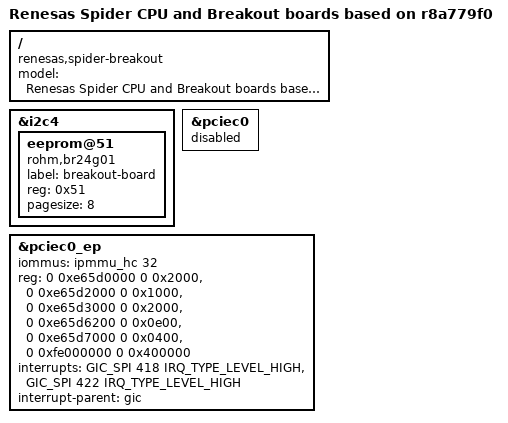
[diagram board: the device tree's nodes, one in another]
// SPDX-License-Identifier: (GPL-2.0 or MIT)
/*
 * Device Tree Source for the Spider CPU and BreakOut boards
 * (PCIe EP mode with DW PCIe eDMA used for NTB transport)
 *
 * Based on the base r8a779f0-spider.dts.
 *
 * Copyright (C) 2025 Renesas Electronics Corp.
 */

/dts-v1/;
#include "r8a779f0-spider-cpu.dtsi"
#include "r8a779f0-spider-ethernet.dtsi"

/ {
	model = "Renesas Spider CPU and Breakout boards based on r8a779f0";
	compatible = "renesas,spider-breakout", "renesas,spider-cpu",
		     "renesas,r8a779f0";
};

&i2c4 {
	eeprom@51 {
		compatible = "rohm,br24g01", "atmel,24c01";
		label = "breakout-board";
		reg = <0x51>;
		pagesize = <8>;
	};
};

&pciec0 {
	status = "disabled";
};

&pciec0_ep {
	iommus = <&ipmmu_hc 32>;
	status = "okay";
	/* Hide eDMA from generic EP users, it is driven by host side remotely */
	reg = <0 0xe65d0000 0 0x2000>, <0 0xe65d2000 0 0x1000>,
	      <0 0xe65d3000 0 0x2000>, <0 0xe65d6200 0 0x0e00>,
	      <0 0xe65d7000 0 0x0400>, <0 0xfe000000 0 0x400000>;
	reg-names = "dbi", "dbi2", "atu", "app", "phy", "addr_space";
	interrupts = <GIC_SPI 418 IRQ_TYPE_LEVEL_HIGH>,
		     <GIC_SPI 422 IRQ_TYPE_LEVEL_HIGH>;
	interrupt-names = "sft_ce", "app";
	interrupt-parent = <&gic>;
};
